# STM32WB35_CM4 register map
File version: 1.2
CPU: CM4 r0p1, little endian, MPU, FPU, 4 interrupt priority bits
Registers are 32-bit, read-write, reset 0x0 unless marked. A register's access mark holds for its fields unless they carry their own. Offsets are from the block's base; [hi:lo] are bit positions; {n}, {i} and the like mark numbered series.

## QUADSPI — QuadSPI interface
Base 0xA0001000
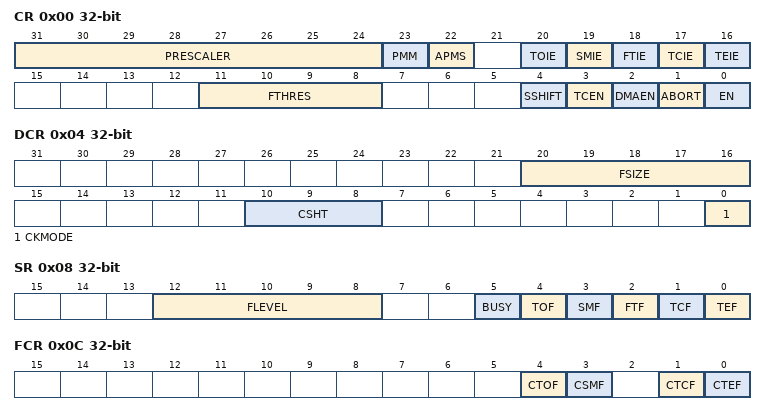
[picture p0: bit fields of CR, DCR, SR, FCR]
0x00 CR — control register
  [31:24] PRESCALER — Clock prescaler
  [23] PMM — Polling match mode
  [22] APMS — Automatic poll mode stop
  [20] TOIE — TimeOut interrupt enable
  [19] SMIE — Status match interrupt enable
  [18] FTIE — FIFO threshold interrupt enable
  [17] TCIE — Transfer complete interrupt enable
  [16] TEIE — Transfer error interrupt enable
  [11:8] FTHRES — FIFO threshold level
  [4] SSHIFT — Sample shift
  [3] TCEN — Timeout counter enable
  [2] DMAEN — DMA enable
  [1] ABORT — Abort request
  [0] EN — Enable
0x04 DCR — device configuration register
  [20:16] FSIZE — FLASH memory size
  [10:8] CSHT — Chip select high time
  [0] CKMODE — Mode 0 / mode 3
0x08 SR ro — status register
  [12:8] FLEVEL — FIFO level
  [5] BUSY
  [4] TOF — Timeout flag
  [3] SMF — Status match flag
  [2] FTF — FIFO threshold flag
  [1] TCF — Transfer complete flag
  [0] TEF — Transfer error flag
0x0C FCR — flag clear register
  [4] CTOF — Clear timeout flag
  [3] CSMF — Clear status match flag
  [1] CTCF — Clear transfer complete flag
  [0] CTEF — Clear transfer error flag
0x10 DLR — data length register
  [31:0] DL — Data length
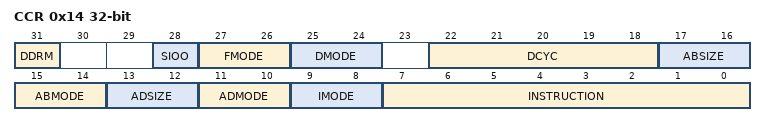
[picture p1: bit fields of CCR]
0x14 CCR — communication configuration register
  [31] DDRM — Double data rate mode
  [28] SIOO — Send instruction only once mode
  [27:26] FMODE — Functional mode
  [25:24] DMODE — Data mode
  [22:18] DCYC — Number of dummy cycles
  [17:16] ABSIZE — Alternate bytes size
  [15:14] ABMODE — Alternate bytes mode
  [13:12] ADSIZE — Address size
  [11:10] ADMODE — Address mode
  [9:8] IMODE — Instruction mode
  [7:0] INSTRUCTION
0x18 AR — address register
  [31:0] ADDRESS
0x1C ABR
  [31:0] ALTERNATE
0x20 DR — data register
  [31:0] DATA
0x24 PSMKR — polling status mask register
  [31:0] MASK — Status mask
0x28 PSMAR — polling status match register
  [31:0] MATCH — Status match
0x2C PIR — polling interval register
  [15:0] INTERVAL — Polling interval
0x30 LPTR — low-power timeout register
  [15:0] TIMEOUT — Timeout period

## SYSCFG — System configuration controller
Base 0x40010000
0x00 MEMRMP — memory remap register
  [2:0] MEM_MODE — Memory mapping selection
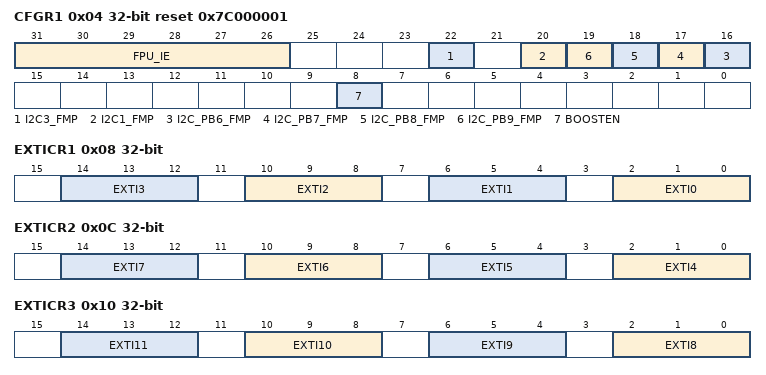
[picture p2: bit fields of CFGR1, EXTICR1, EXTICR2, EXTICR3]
0x04 CFGR1 reset 0x7C000001 — configuration register 1
  [31:26] FPU_IE — Floating Point Unit interrupts enable bits
  [22] I2C3_FMP — I2C3 Fast-mode Plus driving capability activation
  [20] I2C1_FMP — I2C1 Fast-mode Plus driving capability activation
  [n+10] I2C_PB{n}_FMP (n=6..9) — Fast-mode Plus (Fm+) driving capability activation on PB{n}
  [8] BOOSTEN — I/O analog switch voltage booster enable
0x08 EXTICR1 — external interrupt configuration register 1
  [4n+2:4n] EXTI{n} (n=0..3) — EXTI {n} configuration bits
0x0C EXTICR2 — external interrupt configuration register 2
  [4n-14:4n-16] EXTI{n} (n=4..7) — EXTI {n} configuration bits
0x10 EXTICR3 — external interrupt configuration register 3
  [4n-30:4n-32] EXTI{n} (n=8..11) — EXTI {n} configuration bits
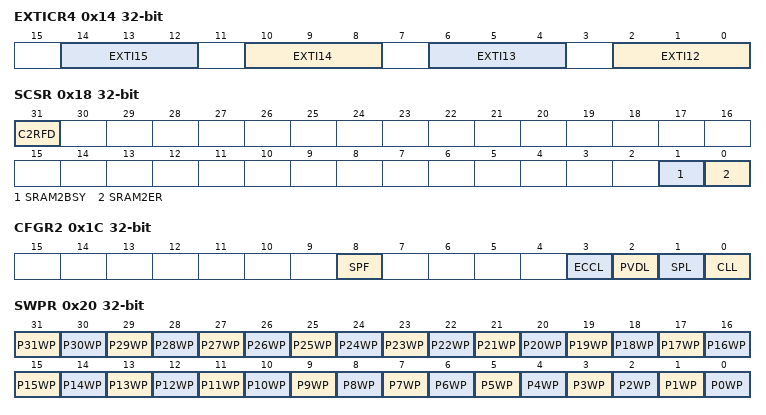
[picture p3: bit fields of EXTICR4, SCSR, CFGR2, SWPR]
0x14 EXTICR4 — external interrupt configuration register 4
  [4n-46:4n-48] EXTI{n} (n=12..15) — EXTI{n} configuration bits
0x18 SCSR access per field
  [31] C2RFD rw — CPU2 SRAM fetch (execution) disable.
  [1] SRAM2BSY ro — SRAM2 busy by erase operation
  [0] SRAM2ER rw — SRAM2 Erase
0x1C CFGR2 access per field
  [8] SPF rw — SRAM2 parity error flag
  [3] ECCL wo — ECC Lock
  [2] PVDL wo — PVD lock enable bit
  [1] SPL wo — SRAM2 parity lock bit
  [0] CLL wo — Cortex-M4 LOCKUP (Hardfault) output enable bit
0x20 SWPR wo — SRAM2 write protection register
  [31] P31WP — SRAM2 page 31 write protection
  [n] P{n}WP (n=0..30)
0x24 SKR wo
  [7:0] KEY — SRAM2 write protection key for software erase
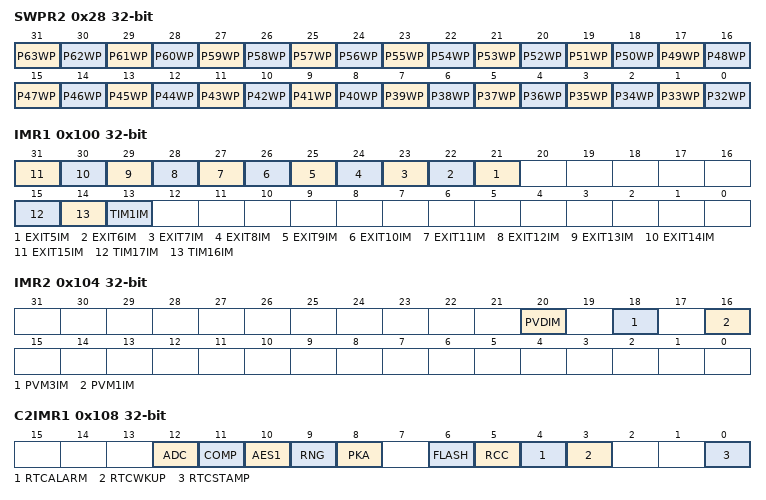
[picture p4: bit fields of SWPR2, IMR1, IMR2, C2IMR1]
0x28 SWPR2 wo — SRAM2 write protection register 2
  [31] P63WP — SRAM2 page 63 write protection
  [n-32] P{n}WP (n=32..62)
0x100 IMR1 — CPU1 interrupt mask register 1
  [n+16] EXIT{n}IM (n=5..15) — Peripheral EXIT{n} interrupt mask to CPU1
  [15] TIM17IM — Peripheral TIM17 interrupt mask to CPU1
  [14] TIM16IM — Peripheral TIM16 interrupt mask to CPU1
  [13] TIM1IM — Peripheral TIM1 interrupt mask to CPU1
0x104 IMR2 — CPU1 interrupt mask register 2
  [20] PVDIM — Peripheral PVD interrupt mask to CPU1
  [18] PVM3IM — Peripheral PVM3 interrupt mask to CPU1
  [16] PVM1IM — Peripheral PVM1 interrupt mask to CPU1
0x108 C2IMR1 — CPU2 interrupt mask register 1
  [12] ADC — Peripheral ADC interrupt mask to CPU2
  [11] COMP — Peripheral COMP interrupt mask to CPU2
  [10] AES1 — Peripheral AES1 interrupt mask to CPU2
  [9] RNG — Peripheral RNG interrupt mask to CPU2
  [8] PKA — Peripheral PKA interrupt mask to CPU2
  [6] FLASH — Peripheral FLASH interrupt mask to CPU2
  [5] RCC — Peripheral RCC interrupt mask to CPU2
  [4] RTCALARM — Peripheral RTCALARM interrupt mask to CPU2
  [3] RTCWKUP — Peripheral RTCWKUP interrupt mask to CPU2
  [0] RTCSTAMP — Peripheral RTCSTAMP interrupt mask to CPU2
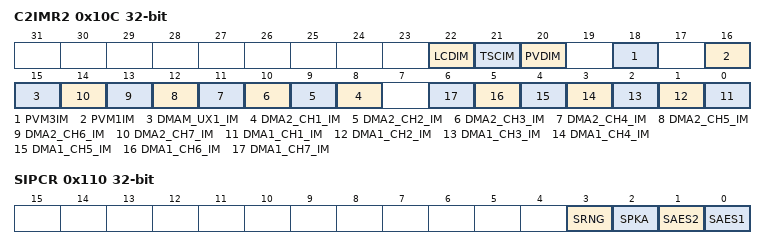
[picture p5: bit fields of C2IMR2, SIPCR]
0x10C C2IMR2 — CPU2 interrupt mask register 1
  [22] LCDIM — Peripheral LCDIM interrupt mask to CPU1
  [21] TSCIM — Peripheral TSCIM interrupt mask to CPU1
  [20] PVDIM — Peripheral PVDIM interrupt mask to CPU1
  [18] PVM3IM — Peripheral PVM3IM interrupt mask to CPU1
  [16] PVM1IM — Peripheral PVM1IM interrupt mask to CPU1
  [15] DMAM_UX1_IM — Peripheral DMAM UX1 interrupt mask to CPU1
  [n+7] DMA2_CH{n}_IM (n=1..7) — Peripheral DMA2 CH{n} interrupt mask to CPU1
  [n-1] DMA1_CH{n}_IM (n=1..7) — Peripheral DMA1 CH{n} interrupt mask to CPU2
0x110 SIPCR — secure IP control register
  [3] SRNG — Enable True RNG security
  [2] SPKA — Enable PKA security
  [1] SAES2 — Enable AES2 security.
  [0] SAES1 — Enable AES1 KEY[7:0] security.
